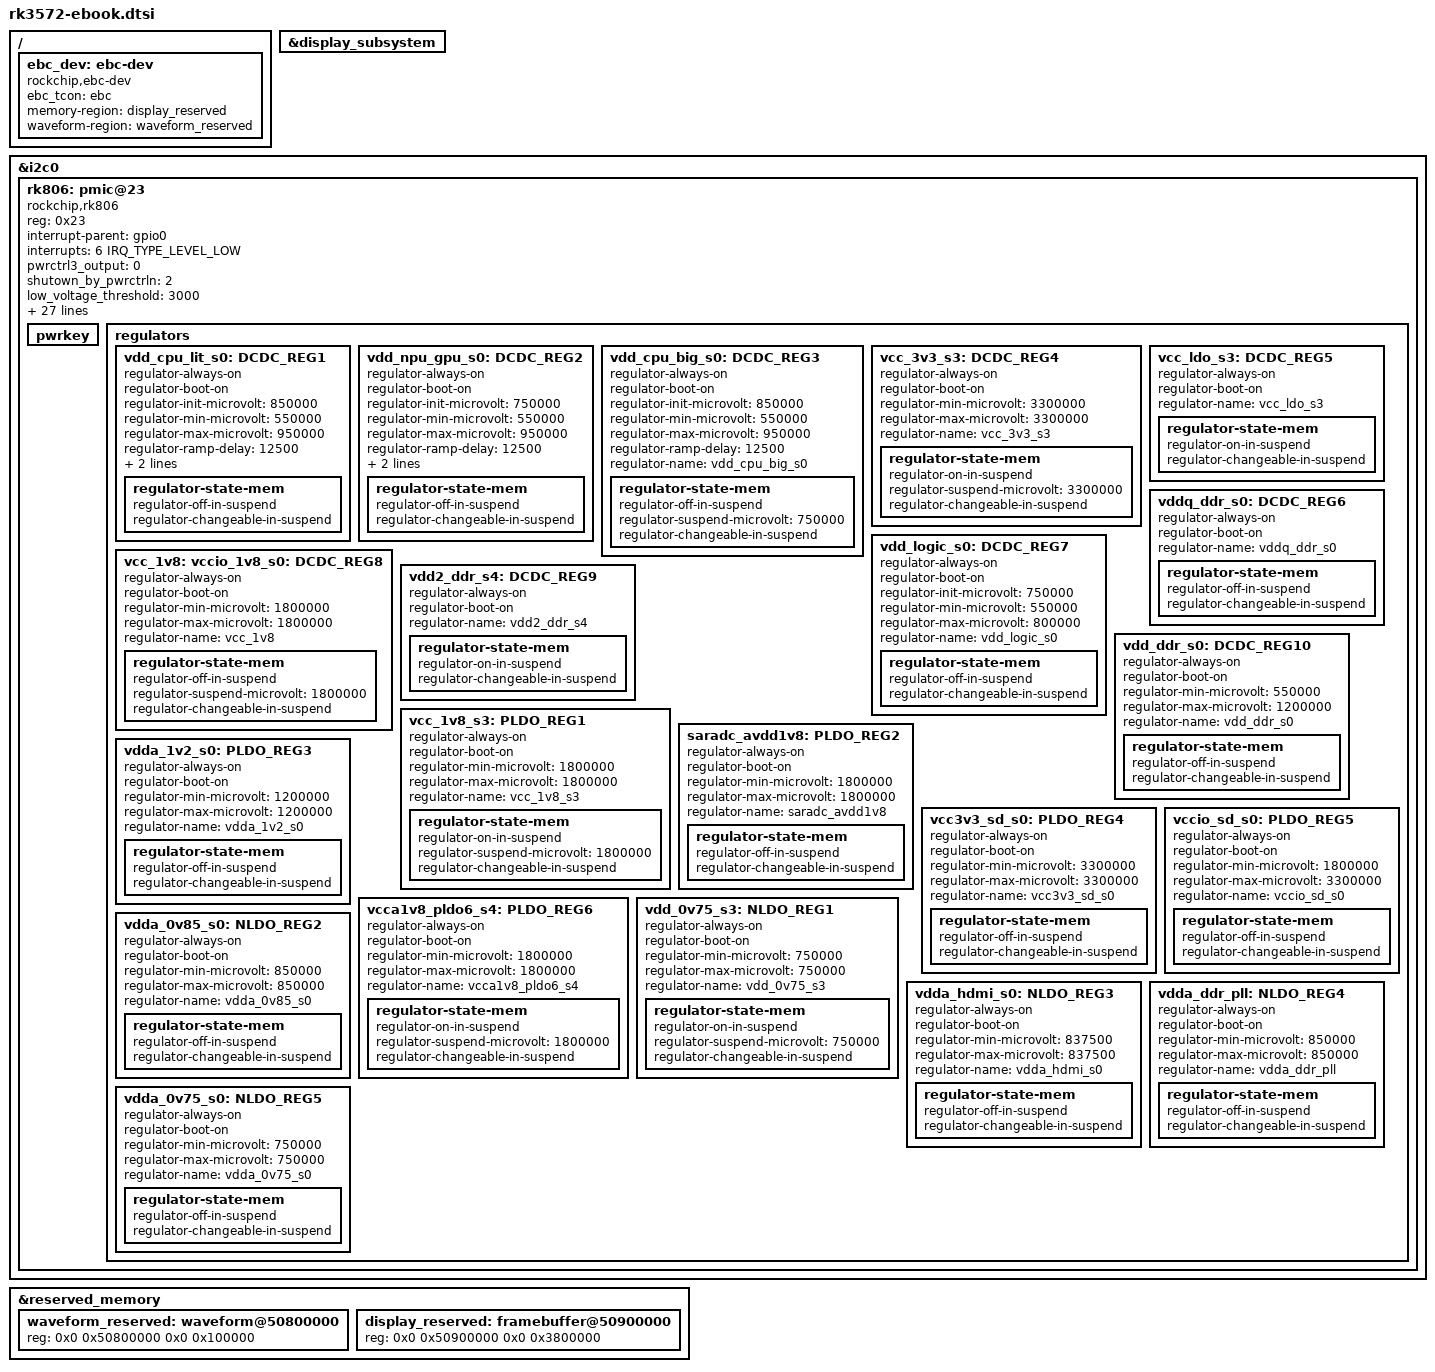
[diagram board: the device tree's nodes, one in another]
// SPDX-License-Identifier: (GPL-2.0+ OR MIT)
/*
 * Copyright (c) 2026 Rockchip Electronics Co., Ltd.
 */
#include <dt-bindings/gpio/gpio.h>
#include <dt-bindings/pinctrl/rockchip.h>

/ {
	ebc_dev: ebc-dev {
		compatible = "rockchip,ebc-dev";
		ebc_tcon = <&ebc>;
		memory-region = <&display_reserved>;
		waveform-region = <&waveform_reserved>;
		//nvmem-cells = <&cpu_code>;
		//nvmem-cell-names = "cpu-code";
		status = "okay";
	};
};

&display_subsystem {
	status = "okay";
};

&i2c0 {
	status = "okay";

	rk806: pmic@23 {
		compatible = "rockchip,rk806";
		reg = <0x23>;

		interrupt-parent = <&gpio0>;
		interrupts = <6 IRQ_TYPE_LEVEL_LOW>;

		//for rk3576 have ultra sleep circuit design
		pwrctrl3_output = <0>;
		shutown_by_pwrctrln = <2>;

		/* 2800mv-3500mv */
		low_voltage_threshold = <3000>;
		/* 2700mv-3400mv */
		shutdown_voltage_threshold = <2700>;
		/* 140 160 */
		shutdown_temperture_threshold = <160>;
		hotdie_temperture_threshold = <115>;

		/* The entered value specifies the delay time (in milliseconds)
		 * that the PMIC waits after receiving the shutdown signal
		 * before executing the power-off action.
		 */
		shutdown-sequence = <2 2 2 0 2 0 2 1 1 2
				     2 2 2 2 2
				     1 0 1 0 0 2>;

		/* low power forced shutdown sequence */
		vb-shutdown-sequence = <2 2 2 0 2 0 2 1 1 2
					2 2 2 2 2
					1 0 1 0 0 2>;
		/* DVS control:
		 * This configuration is tightly bound to the hardware
		 * and requires ATF (Arm Trusted Firmware) support
		 * 0: no effect
		 * 1: controlled by PWRCTRL1
		 * 2: controlled by PWRCTRL2
		 * 3: controlled by PWRCTRL3
		 */
		dvs-suspend-control-by = <0 0 0 0 0 2 0 0 0 2
					  0 0 2 0 0
					  2 2 0 0 0 0>;

		/* 0: restart PMU;
		 * 1: reset all the power off reset registers,
		 *    forcing the state to switch to ACTIVE mode;
		 * 2: Reset all the power off reset registers,
		 *    forcing the state to switch to ACTIVE mode,
		 *    and simultaneously pull down the RESETB PIN for 5mS before releasing
		 */
		pmic-reset-func = <1>;

		vdc-wakeup-enable;

		/* set power key on time */
		pwron-on-time-500ms;

		vcc1-supply = <&vcc_sys>;
		vcc2-supply = <&vcc_sys>;
		vcc3-supply = <&vcc_sys>;
		vcc4-supply = <&vcc_sys>;
		vcc5-supply = <&vcc_sys>;
		vcc6-supply = <&vcc_sys>;
		vcc7-supply = <&vcc_sys>;
		vcc8-supply = <&vcc_sys>;
		vcc9-supply = <&vcc_sys>;
		vcc10-supply = <&vcc_sys>;
		vcc11-supply = <&vcc_ldo_s3>;
		vcc12-supply = <&vcc_sys>;
		vcc13-supply = <&vcc_ldo_s3>;
		vcc14-supply = <&vcc_ldo_s3>;
		vcca-supply = <&vcc_sys>;

		pwrkey {
			status = "okay";
		};

		regulators {
			vdd_cpu_lit_s0: DCDC_REG1 {
				regulator-always-on;
				regulator-boot-on;
				regulator-init-microvolt = <850000>;
				regulator-min-microvolt = <550000>;
				regulator-max-microvolt = <950000>;
				regulator-ramp-delay = <12500>;
				regulator-name = "vdd_cpu_lit_s0";
				regulator-enable-ramp-delay = <400>;
				regulator-state-mem {
					regulator-off-in-suspend;
					regulator-changeable-in-suspend;
				};
			};

			vdd_npu_gpu_s0: DCDC_REG2 {
				regulator-always-on;
				regulator-boot-on;
				regulator-init-microvolt = <750000>;
				regulator-min-microvolt = <550000>;
				regulator-max-microvolt = <950000>;
				regulator-ramp-delay = <12500>;
				regulator-name = "vdd_npu_gpu_s0";
				regulator-enable-ramp-delay = <400>;
				regulator-state-mem {
					regulator-off-in-suspend;
					regulator-changeable-in-suspend;
				};
			};

			vdd_cpu_big_s0: DCDC_REG3 {
				regulator-always-on;
				regulator-boot-on;
				regulator-init-microvolt = <850000>;
				regulator-min-microvolt = <550000>;
				regulator-max-microvolt = <950000>;
				regulator-ramp-delay = <12500>;
				regulator-name = "vdd_cpu_big_s0";
				regulator-state-mem {
					regulator-off-in-suspend;
					regulator-suspend-microvolt = <750000>;
					regulator-changeable-in-suspend;
				};
			};

			vcc_3v3_s3: DCDC_REG4 {
				regulator-always-on;
				regulator-boot-on;
				regulator-min-microvolt = <3300000>;
				regulator-max-microvolt = <3300000>;
				regulator-name = "vcc_3v3_s3";
				regulator-state-mem {
					regulator-on-in-suspend;
					regulator-suspend-microvolt = <3300000>;
					regulator-changeable-in-suspend;
				};
			};

			vcc_ldo_s3: DCDC_REG5 {
				regulator-always-on;
				regulator-boot-on;
				regulator-name = "vcc_ldo_s3";
				regulator-state-mem {
					regulator-on-in-suspend;
					regulator-changeable-in-suspend;
				};
			};

			vddq_ddr_s0: DCDC_REG6 {
				regulator-always-on;
				regulator-boot-on;
				regulator-name = "vddq_ddr_s0";
				regulator-state-mem {
					regulator-off-in-suspend;
					regulator-changeable-in-suspend;
				};
			};

			vdd_logic_s0: DCDC_REG7 {
				regulator-always-on;
				regulator-boot-on;
				regulator-init-microvolt = <750000>;
				regulator-min-microvolt = <550000>;
				regulator-max-microvolt = <800000>;
				regulator-name = "vdd_logic_s0";
				regulator-state-mem {
					regulator-off-in-suspend;
					regulator-changeable-in-suspend;
				};
			};

			vcc_1v8: vccio_1v8_s0: vcca_1v8_s0: DCDC_REG8 {
				regulator-always-on;
				regulator-boot-on;
				regulator-min-microvolt = <1800000>;
				regulator-max-microvolt = <1800000>;
				regulator-name = "vcc_1v8";
				regulator-state-mem {
					regulator-off-in-suspend;
					regulator-suspend-microvolt = <1800000>;
					regulator-changeable-in-suspend;
				};
			};

			vdd2_ddr_s4: DCDC_REG9 {
				regulator-always-on;
				regulator-boot-on;
				regulator-name = "vdd2_ddr_s4";
				regulator-state-mem {
					regulator-on-in-suspend;
					regulator-changeable-in-suspend;
				};
			};

			vdd_ddr_s0: DCDC_REG10 {
				regulator-always-on;
				regulator-boot-on;
				regulator-min-microvolt = <550000>;
				regulator-max-microvolt = <1200000>;
				regulator-name = "vdd_ddr_s0";
				regulator-state-mem {
					regulator-off-in-suspend;
					regulator-changeable-in-suspend;
				};
			};

			vcc_1v8_s3: PLDO_REG1 {
				regulator-always-on;
				regulator-boot-on;
				regulator-min-microvolt = <1800000>;
				regulator-max-microvolt = <1800000>;
				regulator-name = "vcc_1v8_s3";
				regulator-state-mem {
					regulator-on-in-suspend;
					regulator-suspend-microvolt = <1800000>;
					regulator-changeable-in-suspend;
				};
			};

			saradc_avdd1v8: PLDO_REG2 {
				regulator-always-on;
				regulator-boot-on;
				regulator-min-microvolt = <1800000>;
				regulator-max-microvolt = <1800000>;
				regulator-name = "saradc_avdd1v8";
				regulator-state-mem {
					regulator-off-in-suspend;
					regulator-changeable-in-suspend;
				};
			};

			vdda_1v2_s0: PLDO_REG3 {
				regulator-always-on;
				regulator-boot-on;
				regulator-min-microvolt = <1200000>;
				regulator-max-microvolt = <1200000>;
				regulator-name = "vdda_1v2_s0";
				regulator-state-mem {
					regulator-off-in-suspend;
					regulator-changeable-in-suspend;
				};
			};

			vcc3v3_sd_s0: PLDO_REG4 {
				regulator-always-on;
				regulator-boot-on;
				regulator-min-microvolt = <3300000>;
				regulator-max-microvolt = <3300000>;
				regulator-name = "vcc3v3_sd_s0";
				regulator-state-mem {
					regulator-off-in-suspend;
					regulator-changeable-in-suspend;
				};
			};

			vccio_sd_s0: PLDO_REG5 {
				regulator-always-on;
				regulator-boot-on;
				regulator-min-microvolt = <1800000>;
				regulator-max-microvolt = <3300000>;
				regulator-name = "vccio_sd_s0";
				regulator-state-mem {
					regulator-off-in-suspend;
					regulator-changeable-in-suspend;
				};
			};

			vcca1v8_pldo6_s4: PLDO_REG6 {
				regulator-always-on;
				regulator-boot-on;
				regulator-min-microvolt = <1800000>;
				regulator-max-microvolt = <1800000>;
				regulator-name = "vcca1v8_pldo6_s4";
				regulator-state-mem {
					regulator-on-in-suspend;
					regulator-suspend-microvolt = <1800000>;
					regulator-changeable-in-suspend;
				};
			};

			vdd_0v75_s3: NLDO_REG1 {
				regulator-always-on;
				regulator-boot-on;
				regulator-min-microvolt = <750000>;
				regulator-max-microvolt = <750000>;
				regulator-name = "vdd_0v75_s3";
				regulator-state-mem {
					regulator-on-in-suspend;
					regulator-suspend-microvolt = <750000>;
					regulator-changeable-in-suspend;
				};
			};

			vdda_0v85_s0: NLDO_REG2 {
				regulator-always-on;
				regulator-boot-on;
				regulator-min-microvolt = <850000>;
				regulator-max-microvolt = <850000>;
				regulator-name = "vdda_0v85_s0";
				regulator-state-mem {
					regulator-off-in-suspend;
					regulator-changeable-in-suspend;
				};
			};

			vdda_hdmi_s0: NLDO_REG3 {
				regulator-always-on;
				regulator-boot-on;
				regulator-min-microvolt = <837500>;
				regulator-max-microvolt = <837500>;
				regulator-name = "vdda_hdmi_s0";
				regulator-state-mem {
					regulator-off-in-suspend;
					regulator-changeable-in-suspend;
				};
			};

			vdda_ddr_pll: NLDO_REG4 {
				regulator-always-on;
				regulator-boot-on;
				regulator-min-microvolt = <850000>;
				regulator-max-microvolt = <850000>;
				regulator-name = "vdda_ddr_pll";
				regulator-state-mem {
					regulator-off-in-suspend;
					regulator-changeable-in-suspend;
				};
			};

			vdda_0v75_s0: NLDO_REG5 {
				regulator-always-on;
				regulator-boot-on;
				regulator-min-microvolt = <750000>;
				regulator-max-microvolt = <750000>;
				regulator-name = "vdda_0v75_s0";
				regulator-state-mem {
					regulator-off-in-suspend;
					regulator-changeable-in-suspend;
				};
			};
		};
	};
};

&reserved_memory {
	waveform_reserved: waveform@50800000 {
		reg = <0x0 0x50800000 0x0 0x100000>;
	};

	display_reserved: framebuffer@50900000 {
		reg = <0x0 0x50900000 0x0 0x3800000>;
	};
};

/*
&rockchip_suspend {
	rockchip,sleep-debug-en = <1>;

	rockchip,regulator-off-in-mem-lite =
		<&vdd_cpu_lit_s0>, <&vdd_npu_gpu_s0>, <&vdd_cpu_big_s0>, <&vddq_ddr_s0>, <&vdd_logic_s0>,
		<&vcc_1v8>, <&vdd_ddr_s0>, <&saradc_avdd1v8>, <&vcca1v2_s0>, <&vcc3v3_sd_s0>,
		<&vccio_sd_s0>, <&vdda_0v85_s0>, <&vdda_hdmi_s0>, <&vdda_ddr_pll>, <&vdda_0v75_s0>;
	rockchip,regulator-on-in-mem-lite =
		<&vcc_3v3_s3>, <&vcc_ldo_s3>, <&vdd2_ddr_s4>, <&vcc_1v8_s3>, <&vcca1v8_pldo6_s4>, <&vdd_0v75_s3>;

	rockchip,regulator-off-in-mem =
		<&vdd_cpu_lit_s0>, <&vdd_npu_gpu_s0>, <&vdd_cpu_big_s0>, <&vddq_ddr_s0>, <&vdd_logic_s0>,
		<&vcc_1v8>, <&vdd_ddr_s0>, <&saradc_avdd1v8>, <&vcca1v2_s0>, <&vcc3v3_sd_s0>,
		<&vccio_sd_s0>, <&vdda_0v85_s0>, <&vdda_hdmi_s0>, <&vdda_ddr_pll>, <&vdda_0v75_s0>;
	rockchip,regulator-on-in-mem =
		<&vcc_3v3_s3>, <&vcc_ldo_s3>, <&vdd2_ddr_s4>, <&vcc_1v8_s3>, <&vcca1v8_pldo6_s4>, <&vdd_0v75_s3>;

	rockchip,regulator-off-in-mem-ultra =
		<&vdd_cpu_lit_s0>, <&vdd_npu_gpu_s0>, <&vdd_cpu_big_s0>, <&vcc_3v3_s3>, <&vcc_ldo_s3>, <&vddq_ddr_s0>, <&vdd_logic_s0>,
		<&vcc_1v8>, <&vdd_ddr_s0>, <&vcc_1v8_s3>, <&saradc_avdd1v8>, <&vcca1v2_s0>, <&vcc3v3_sd_s0>,
		<&vccio_sd_s0>, <&vdd_0v75_s3>, <&vdda_0v85_s0>, <&vdda_hdmi_s0>, <&vdda_ddr_pll>, <&vdda_0v75_s0>;
	rockchip,regulator-on-in-mem-ultra = <&vdd2_ddr_s4>, <&vcca1v8_pldo6_s4>;

	status = "okay";
};
*/
